# R9A02G021 register map
Vendor: Renesas Electronics Corporation; Series: RISC-V; File version: 1.10.00 + 202304131714_CPU
CPU: other r0p0, little endian, no MPU, no FPU, VTOR, 4 interrupt priority bits, 32 interrupts
Registers are 8-bit, read-write, reset 0x0 unless marked. A register's access mark holds for its fields unless they carry their own. Offsets are from the block's base; [hi:lo] are bit positions; {n}, {i} and the like mark numbered series; 'fields as' and 'values as' point back to an identical list.

## SRAM — SRAM Control
Base 0x40002000
0x00 PARIOAD — SRAM Parity Error Operation After Detection Register
  [0] OAD — Operation After Detection
    0=Non-maskable interrupt; 1=Reset
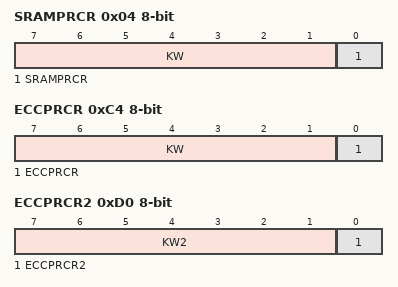
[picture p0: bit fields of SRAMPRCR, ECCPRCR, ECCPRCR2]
0x04 SRAMPRCR — SRAM Protection Register
  [7:1] KW wo — Write Key Code
  [0] SRAMPRCR — Register Write Control
    0=Disable writes to protected registers; 1=Enable writes to protected registers
0xC0 ECCMODE — ECC Operating Mode Control Register
  [1:0] ECCMOD — ECC Operating Mode Select
    0=Disable ECC function; 1=Setting prohibited; 2=Enable ECC function without error checking; 3=Enable ECC function with error checking
0xC1 ECC2STS — ECC 2-Bit Error Status Register
  [0] ECC2ERR — ECC 2-Bit Error Status
    0=No 2-bit ECC error occurred; 1=2-bit ECC error occurred
0xC2 ECC1STSEN — ECC 1-Bit Error Information Update Enable Register
  [0] E1STSEN — ECC 1-Bit Error Information Update Enable
    0=Disable updating of 1-bit ECC error information; 1=Enable updating of 1-bit ECC error information
0xC3 ECC1STS — ECC 1-Bit Error Status Register
  [0] ECC1ERR — ECC 1-Bit Error Status
    0=No 1-bit ECC error occurred; 1=1-bit ECC error occurred
0xC4 ECCPRCR — ECC Protection Register
  [7:1] KW wo — Write Key Code
    120=Enable write to the ECCPRCR bit; other=Others (Disable write to the ECCPRCR bit)
  [0] ECCPRCR — Register Write Control
    0=Disable writes to the protected registers; 1=Enable writes to the protected registers
0xD0 ECCPRCR2 — ECC Protection Register 2
  [7:1] KW2 wo — Write Key Code
    120=Enable write to the ECCPRCR2 bit; other=Others (Disable write to the ECCPRCR2 bit)
  [0] ECCPRCR2 — Register Write Control
    values as ECCPRCR.ECCPRCR
0xD4 ECCETST — ECC Test Control Register
  [0] TSTBYP — ECC Bypass Select
    0=Disable ECC bypass; 1=Enable ECC bypass
0xD8 ECCOAD — SRAM ECC Error Operation After Detection Register
  fields as PARIOAD

## BUS — BUS Control
Base 0x40003000
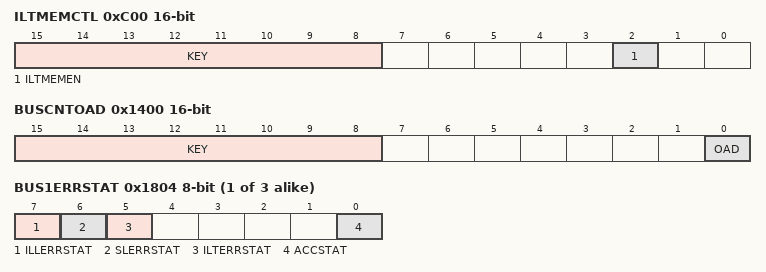
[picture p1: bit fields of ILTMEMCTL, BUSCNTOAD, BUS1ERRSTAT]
0xC00 ILTMEMCTL 16-bit — Illicit Memory Access Detection Control Register
  [15:8] KEY — Key Code
  [2] ILTMEMEN — Illicit Memory Access Detection Enable
    0=Disabled; 1=Enabled
0x1000 BUSMCNTINST 16-bit — Control Register INST
  [15] IERES — Ignore Error Responses
    0=Bus errors are reported; 1=Bus errors are not reported
0x1004 BUSMCNTDAT 16-bit — Control Register DAT
  fields as BUSMCNTINST
0x1008 BUSMCNTDMA 16-bit — Control Register DMA
  fields as BUSMCNTINST
0x1400 BUSCNTOAD 16-bit — Bus Control Error Operation After Detection Register
  [15:8] KEY — Key Code
  [0] OAD — Operation After Detection
    0=Non-maskable interrupt; 1=Reset
{0x17F0+0x10*i} BUS{i}ERRADD 32-bit ro reset not defined (i=1..3) — Bus Error Address Register {i}
  [31:0] BERAD — Bus Error Address
{0x17F4+0x10*i} BUS{i}ERRSTAT ro (i=1..3) — BUS Error Status Register {i}
  [7] ILLERRSTAT — Illegal Address Access Error Status flag
    0=No bus error occurred; 1=Bus error occurred
  [6] SLERRSTAT — Slave Bus Error Status flag
    0=No bus error occurred; 1=Bus error occurred
  [5] ILTERRSTAT — Illicit Memory Access Error Status flag
    0=No bus error occurred; 1=Bus error occurred
  [0] ACCSTAT — Error Access Status flag
    0=Read access; 1=Write access

## DTC — Data Transfer Controller
Base 0x40005400
0x00 DTCCR reset 0x8 — DTC Control Register
  [4] RRS — DTC Transfer Information Read Skip Enable
    0=Transfer information read is not skipped; 1=Transfer information read is skipped when vector numbers match
0x04 DTCVBR 32-bit — DTC Vector Base Register
0x0C DTCST — DTC Module Start Register
  [0] DTCST — DTC Module Start
    0=DTC module stopped; 1=DTC module started
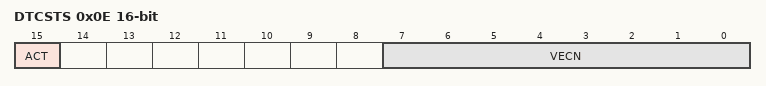
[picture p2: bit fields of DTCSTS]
0x0E DTCSTS 16-bit ro — DTC Status Register
  [15] ACT — DTC Active Flag
    0=DTC transfer operation is not in progress; 1=DTC transfer operation is in progress
  [7:0] VECN — DTC-Activating Vector Number Monitoring
